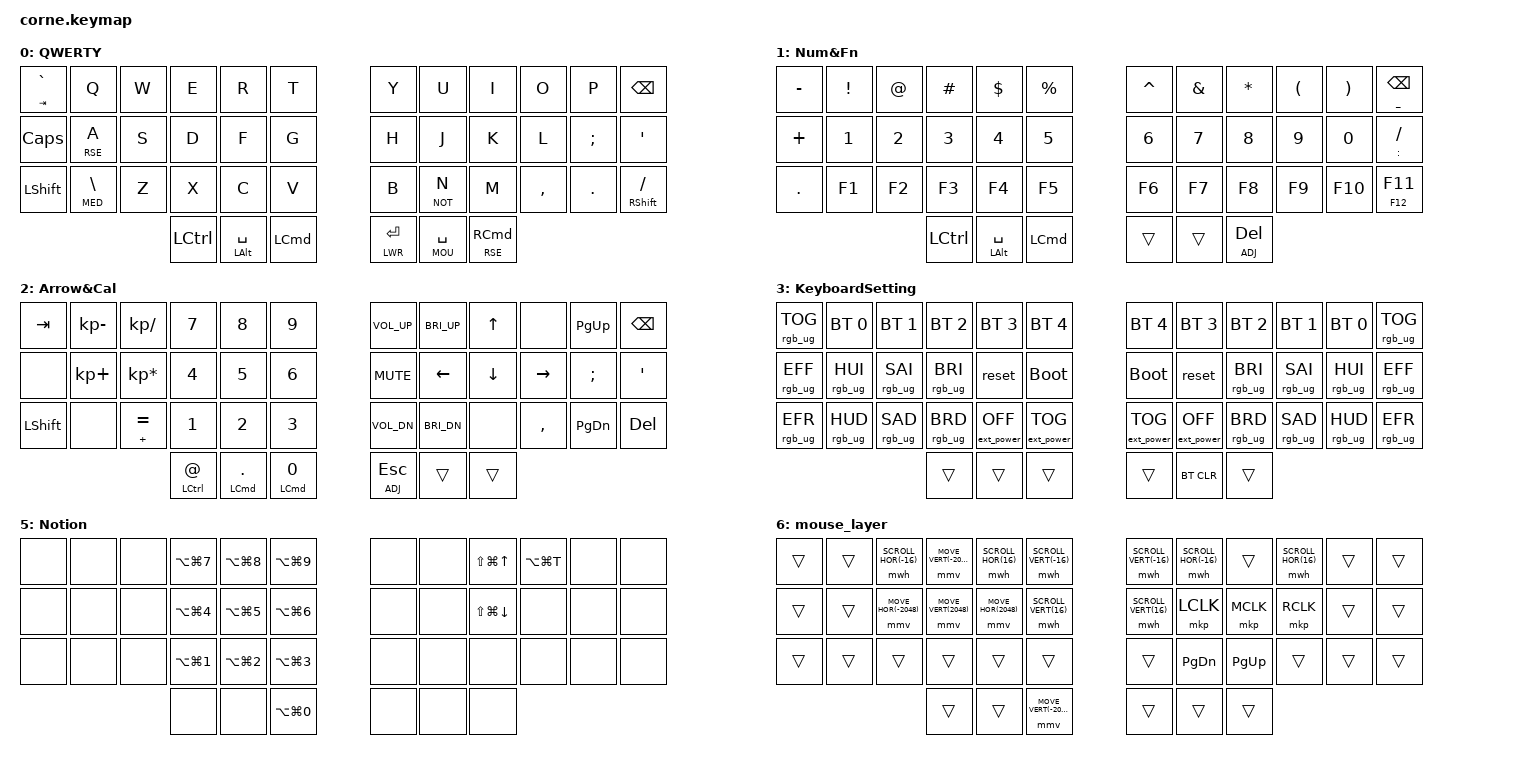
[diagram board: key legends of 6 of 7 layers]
/*
 * Copyright (c) 2020 The ZMK Contributors
 *
 * SPDX-License-Identifier: MIT
 */

#include <behaviors.dtsi>
#include <dt-bindings/zmk/bt.h>
#include <dt-bindings/zmk/ext_power.h>
#include <dt-bindings/zmk/keys.h>
#include <dt-bindings/zmk/mouse.h>
#include <dt-bindings/zmk/rgb.h>

#define DEF 0
#define LWR 1
#define RSE 2
#define ADJ 3
#define MED 4
#define NOT 5
#define MOU 6

&lt {
    tapping-term-ms = <250>;
    flavor = "tap-preferred";
    };

&mt { 
    quick_tap_ms=<200>; 
    };

&mmv {
     time-to-max-speed-ms = <256>;
     acceleration-exponent = <3>;
};

&mwh {
     time-to-max-speed-ms = <48>;
     acceleration-exponent = <4>;
};

/ {
	chosen {
		zmk,underglow = &led_strip;
	};
};

/*                            KEY POSITIONS
  ╭─────────────────────────────╮         ╭──────────────────────────────╮
  │  0   1Q   2W   3E   4R   5T │         │  6Y   7U   8I   9O  10P  11| │
  │ 12  13A  14S  15D  16F  17G │         │ 18H  19J  20K  21L  22;  23' │
  │ 24  25\  26z  27x  28c  29v ╰───╮ ╭───╯ 30b  31n  32m  33,  34.  35/ │
  ╰──────────────────╮ 36   37   38 │ │ 39   40   41 ╭───────────────────╯
                     ╰──────────────╯ ╰──────────────╯            */

/ {
    combos {
        // Symbols / Operations
        compatible = "zmk,combos";
        combo_lbkt {
            timeout-ms = <50>;
            key-positions = <4 5>; // KP: RT
            bindings = <&kp LBKT>; // [
        };
        combo_rbkt {
            timeout-ms = <50>;
            key-positions = <6 7>; // KP: YU
            bindings = <&kp RBKT>; // ]
        };
        combo_lpar {
            timeout-ms = <50>;
            key-positions = <16 17>; // KP: FG
            bindings = <&kp LPAR>; // (
        };
        combo_rpar {
            timeout-ms = <50>;
            key-positions = <18 19>; // KP: HJ
            bindings = <&kp RPAR>; // )
        };
        combo_lbrc {
            timeout-ms = <50>;
            key-positions = <28 29>; // KP: VB
            bindings = <&kp LBRC>; // {
        };
        combo_rbrc {
            timeout-ms = <50>;
            key-positions = <30 31>; // KP: NM
            bindings = <&kp RBRC>; // }
        };   
        combo_fslh {
            timeout-ms = <50>;
            key-positions = <19 30>; // KP: NJ
            bindings = <&kp FSLH>; // forward slash
        };
        combo_bslh {
            timeout-ms = <50>;
            key-positions = <16 29>; // KP: BF
            bindings = <&kp BSLH>; // backs lash
        };    
        combo_equal {
            timeout-ms = <50>;
            key-positions = <9 10>; // KP: op
            bindings = <&mt GREATER_THAN EQUAL>; // > (= & +)
        };  
        combo_minus2 {
            timeout-ms = <50>;
            key-positions = <8 9>; // KP: io
            bindings = <&mt LESS_THAN MINUS>; // (< & -) 
        }; 
        combo_excl {
            timeout-ms = <50>;
            key-positions = <33 34>; // KP: ,.
            bindings = <&kp EXCLAMATION>; // !
        };  
        combo_dollar {
            timeout-ms = <50>;
            key-positions = <27 28>; // KP: xc
            bindings = <&kp DOLLAR>; // ($)
        }; 
        combo_under {
            timeout-ms = <50>;
            key-positions = <29 30>; // KP: BN
            bindings = <&kp UNDER>; // (_)
        };
        combo_minus {
            timeout-ms = <50>;
            key-positions = <17 18>; // KP: GH
            bindings = <&kp MINUS>; // (-)
        };
        combo_pipe {
            timeout-ms = <50>;
            key-positions = <5 6>; // KP: TY
            bindings = <&kp PIPE>; // (|)
        };
        combo_f12 {
            timeout-ms = <50>;
            key-positions = <10 11>; // KP: top right
            bindings = <&kp F12>; // F12
        };

        // arrow keys
        combo_left {
            timeout-ms = <50>;
            key-positions = <14 15>; // KP: SD
            bindings = <&kp LEFT>; 
        };    
        combo_right {
            timeout-ms = <50>;
            key-positions = <15 16>; // KP: DF
            bindings = <&kp RIGHT>; 
        };   
        combo_up{
            timeout-ms = <50>;
            key-positions = <3 15>; // KP: ED 
            bindings = <&kp UP>; 
        };   
        combo_down {
            timeout-ms = <50>;
            key-positions = <15 27>; // KP: DX
            bindings = <&kp DOWN>; 
        };   

        // Power ESC ENTER
        combo_k_pwr {
            timeout-ms = <50>;
            key-positions = <0 38>;
            bindings = <&kp K_PWR>; // Power (Keyboard)
        };
        combo_esc {
            timeout-ms = <50>;
            key-positions = <0 1>;
            bindings = <&kp ESC>; // ESC
        };
        combo_left_bspc {
            timeout-ms = <50>;
            key-positions = <12 13>; // KP: CAP A
            bindings = <&kp BSPC>; // backspace
        };
        combo_enter {
            timeout-ms = <50>;
            key-positions = <19 20>; // KP: JK
            bindings = <&kp ENTER>; // enter
        };

    };
}; 

/ {
        behaviors {
                hm: homerow_mods {
                        compatible = "zmk,behavior-hold-tap";
                        label = "HOMEROW_MODS";
                        #binding-cells = <2>;
                        tapping-term-ms = <200>;
                        quick_tap_ms = <0>;
                        flavor = "tap-preferred";
                        bindings = <&kp>, <&kp>;
                };
                hs: homerow_shifts {
                        compatible = "zmk,behavior-hold-tap";
                        label = "HOMEROW_SHIFTS";
                        #binding-cells = <2>;
                        tapping-term-ms = <150>;
                        quick_tap_ms = <0>;
                        flavor = "balanced";
                        bindings = <&kp>, <&kp>;
                };
                td: tapdance {
                        compatible = "zmk,behavior-hold-tap";
                        label = "TAPDANCE";
                        #binding-cells = <2>;
                        tapping-term-ms = <190>;
                        quick_tap_ms = <0>;
                        flavor = "tap-preferred";
                        bindings = <&kp>, <&kp>;
                };
        };
        keymap {
                compatible = "zmk,keymap";

                default_layer {
                        label = "QWERTY";
// -----------------------------------------------------------------------------------------
// |`/~ |  Q  |  W  |  E  |  R  |  T  |   |  Y  |  U  |  I  |  O  |  P  | F11/F12 |
// | CAP|  A  |  S  |  D  |  F  |  G  |   |  H  |  J  |  K  |  L  |  ;  |  '  |
// |SHFT| MED\|  Z  |  X  |  C  |  V  |   |  B  |  N  |  M  |  ,  |  .  |  /  |
//            | CTRL | ALT | COMMEND  |   | LWR ENTER| SPACE | RSE FRCMD | 
                        bindings = <
   &mt TAB GRAVE &kp Q &kp W &kp E &kp R &kp T                 &kp Y  &kp U  &kp I &kp O   &kp P  &kp BSPC
   &kp CAPS      &lt RSE A &kp S &kp D &kp F &kp G             &kp H  &kp J  &kp K &kp L   &kp SEMI &kp SQT
   &kp LSHFT     &lt MED BSLH  &kp Z &kp X &kp C &kp V         &kp B  &lt NOT N  &kp M &kp COMMA &kp PERIOD &mt RSHFT FSLH
            &kp LCTRL &mt LALT SPACE &kp LCMD                  &lt LWR ENTER &lt MOU SPACE &lt RSE RCMD
                        >;
                };
                lower_layer {
                        label = "Num&Fn";
// -----------------------------------------------------------------------------------------
// |  -  |  !  |  @  |  #  |  $  |  %  |   |  ^  |  &  |  *  |  (  |  )  | BSPC/-  |
// |  +  |  1  |  2  |  3  |  4  |  5  |   |  6  |  7  |  8  |  9  |  0  | :/"     |
// |  .  |  F1 |  F2 |  F3 |  F4 |  F5 |   |  F6 |  F7 |  F8 |  F9 | F10 | F11/F12 |
//                    | GUI |     | SPC |   | ENT |     | ALT |
                        bindings = <
   &kp MINUS &kp EXCL &kp AT &kp HASH &kp DLLR &kp PRCNT         &kp CARET &kp AMPS &kp STAR &kp LPAR &kp RPAR &mt UNDER BSPC
   &kp PLUS &kp N1   &kp N2 &kp N3   &kp N4   &kp N5             &kp N6    &kp N7   &kp N8   &kp N9   &kp N0   &mt COLON SLASH
   &kp DOT  &kp F1   &kp F2 &kp F3   &kp F4   &kp F5             &kp F6    &kp F7   &kp F8   &kp F9   &kp F10  &mt F12 F11
                        &kp LCTRL &mt LALT SPACE &kp LCMD         &trans &trans &lt ADJ DEL
                        >;
                };

                raise_layer {
                    label = "Arrow&Cal";
// -----------------------------------------------------------------------------------------
// | TAB |  -  |  /  |  7  |  8  |  9  |   | VOLU| BRIU|  UP |      | PGUP |BSPC|
// |     |  +  |  *  |  4  |  5  |  6  |   | MUT | LEFT|DOWN | RGHT |  ；   |  ‘ |
// |SHFT |     |  =  |  1  |  2  |  3  |   | VOLD| BRID|     | COMMA| PGDN |DEL |
//                   |     |     |  0  |   | ADJ |     |     |
                        bindings = <
   &kp TAB     &kp KP_MINUS  &kp KP_SLASH  &kp N7 &kp N8 &kp N9      &kp C_VOL_UP &kp C_BRI_UP &kp UP &none &kp PG_UP &kp BSPC
   &none       &kp KP_PLUS &kp KP_MULTIPLY &kp N4 &kp N5 &kp N6      &kp C_MUTE   &kp LEFT     &kp DOWN &kp RIGHT &kp SEMI &kp SQT
   &kp LSHFT   &none     &mt PLUS EQUAL  &kp N1 &kp N2 &kp N3        &kp C_VOL_DN &kp C_BRI_DN &none    &kp COMMA &kp PG_DN &kp DEL
                        &mt LCTRL AT &mt LCMD DOT &mt LCMD N0        &lt ADJ ESC &trans &trans
                        >;
                };
                adjust_layer {
                    label = "KeyboardSetting";
// -----------------------------------------------------------------------------------------------
// | RGBTOG| BT0 | BT1 | BT2 | BT3  | BT4  |   | BT4  | BT3  | BT2 | BT1 | BT0 | RGBTOG|
// | MOD+  | HUE+| SAT+| VAL+|      | BLDR |   | BLDR |      | VAL+| SAT+| HUE+| MOD+  |
// | MOD-  | HUE-| SAT-| VAL-|EP_OFF|EP_TOG|   |EP_TOG|EP_OFF| VAL-| SAT-| HUE-| MOD-  |
//                     |     | BTCLR|      |   |      | BTCLR|     |
                        bindings = <
   &rgb_ug RGB_TOG  &bt BT_SEL 0    &bt BT_SEL 1     &bt BT_SEL 2    &bt BT_SEL 3      &bt BT_SEL 4             &bt BT_SEL 4      &bt BT_SEL 3      &bt BT_SEL 2    &bt BT_SEL 1    &bt BT_SEL 0    &rgb_ug RGB_TOG
   &rgb_ug RGB_EFF  &rgb_ug RGB_HUI &rgb_ug RGB_SAI  &rgb_ug RGB_BRI &reset            &bootloader              &bootloader       &reset            &rgb_ug RGB_BRI &rgb_ug RGB_SAI &rgb_ug RGB_HUI &rgb_ug RGB_EFF
   &rgb_ug RGB_EFR  &rgb_ug RGB_HUD &rgb_ug RGB_SAD  &rgb_ug RGB_BRD &ext_power EP_OFF &ext_power EP_TOG        &ext_power EP_TOG &ext_power EP_OFF &rgb_ug RGB_BRD &rgb_ug RGB_SAD &rgb_ug RGB_HUD &rgb_ug RGB_EFR
                                                                        &trans &trans &trans                    &trans &bt BT_CLR &trans
                        >;
                };
                    media_layer {
                    label = "Media";
                        bindings = <
   &none   &none  &kp LC(LG(W))  &none  &none  &none                              &kp C_VOL_UP   &kp C_BRI_UP  &kp LS(LA(UP))  &none  &none  &none
   &none   &kp LC(LG(A))  &none  &kp LS(LG(N3))  &kp LS(LG(N4))  &kp LS(LG(N5))   &kp C_MUTE   &kp LG(LBKT)  &mt LC(LA(LG(K))) LS(LA(DOWN))  &kp LG(RBKT)   &none  &none
   &none   &none  &none  &none  &kp LC(LA(LG(C)))  &none                          &kp C_VOL_DN   &kp C_BRI_DN  &none  &none  &none  &none
   &kp LC(LA(LG(LEFT))) &kp LC(LA(LG(SPACE))) &kp LC(LA(LG(RIGHT)))               &kp LC(LA(LG(LEFT))) &kp LC(LA(LG(SPACE))) &kp LC(LA(LG(RIGHT)))
                        >;
                };
                    notion_layer {
                    label = "Notion";
                        bindings = <
   &none   &none  &none  &kp LA(LG(N7))  &kp LA(LG(N8))  &kp LA(LG(N9))     &none   &none  &kp LS(LG(UP))  &kp LA(LG(T))  &none  &none
   &none   &none  &none  &kp LA(LG(N4))  &kp LA(LG(N5))  &kp LA(LG(N6))     &none   &none  &kp LS(LG(DOWN))  &none  &none  &none
   &none   &none  &none  &kp LA(LG(N1))  &kp LA(LG(N2))  &kp LA(LG(N3))     &none   &none  &none  &none  &none  &none
                       &none   &none  &kp LA(LG(N0))                        &none   &none  &none
                        >;
                };
                mouse_layer {
                        bindings = <
   &trans     &trans       &mwh SCROLL_HOR(-16)  &mmv MOVE_VERT(-2048)  &mwh SCROLL_HOR(16)    &mwh SCROLL_VERT(-16) &mwh SCROLL_VERT(-16) &mwh SCROLL_HOR(-16)  &trans     &mwh SCROLL_HOR(16)  &trans  &trans
   &trans     &trans       &mmv MOVE_HOR(-2048)  &mmv MOVE_VERT(2048)   &mmv MOVE_HOR(2048)    &mwh SCROLL_VERT(16)  &mwh SCROLL_VERT(16)  &mkp LCLK             &mkp MCLK  &mkp RCLK            &trans  &trans
   &trans     &trans       &trans                &trans                 &trans                 &trans                &trans                &kp PG_DN             &kp PG_UP  &trans               &trans  &trans
                           &trans                &trans                 &mmv MOVE_VERT(-2048)                                              &trans                &trans     &trans
                        >;
                };
        };
};
